# PY32F0xx_DFP register map
Vendor: Puya; Series: PY32F0; File version: 1.0.0
Arm 32-bit Cortex-M0+ Microcontroller based device, CPU clock up to 48 MHz.
CPU: CM0+ r0p1, little endian, no MPU, no FPU, 4 interrupt priority bits
Registers are 32-bit, read-write, reset 0x0 unless marked. A register's access mark holds for its fields unless they carry their own. Offsets are from the block's base; lines under a group give offsets from that group; [hi:lo] are bit positions; {n}, {i} and the like mark numbered series; 'fields as' and 'values as' point back to an identical list; <NAME> marks a mode.

## Memory map
0x40002000 TIM14 size 0x400 — General purpose timer
0x40003000 IWDG size 0x400 — Independent watchdog
0x40007000 PWR size 0x400 — Power control
0x40007C00 LPTIM1 size 0x400 — Low power timer
0x40010000 SYSCFG size 0x30 — System configuration controller
0x40010200 COMP1 size 0x10 — Comparator 1
0x40010210 COMP2 size 0x10 — Comparator2
0x40012C00 TIM1 size 0x400 — Advanced timer
0x40015800 DBGMCU size 0x400 — Debug support
0x40021000 RCC size 0x400 — Reset and clock control
0x40021800 EXTI size 0x400 — External interrupt/event controller
0x40022000 FLASH size 0x400
0x40023000 CRC size 0x400 — CRC calculation unit
0x50000000 GPIOA size 0x400 — General-purpose I/Os
0x50000400 GPIOB size 0x400 — General-purpose I/Os
0x50000800 GPIOC size 0x400

## Interrupts
3 FLASH — FLASH global Interrupt
4 RCC — RCC global Interrupt
5 EXTI0_1 (EXTI) — EXTI Line 0 and 1 Interrupt
6 EXTI2_3 (EXTI) — EXTI Line 2 and 3 Interrupt
7 EXTI4_15 (EXTI) — EXTI Line 4 to 15 Interrupt
12 ADC_COMP (COMP1, COMP2) — ADC and COMP Interrupts
13 TIM1_BRK_UP_TRG_COM (TIM1) — TIM1 Break, Update, Trigger and Commutation Interrupt
14 TIM1_CC (TIM1) — TIM1 Capture Compare Interrupt
17 LPTIM1_DAC (LPTIM1) — LPTIM1, DAC global Interrupts
19 TIM14 — TIM14 global Interrupt

## COMP1 — Comparator 1
Base 0x40010200
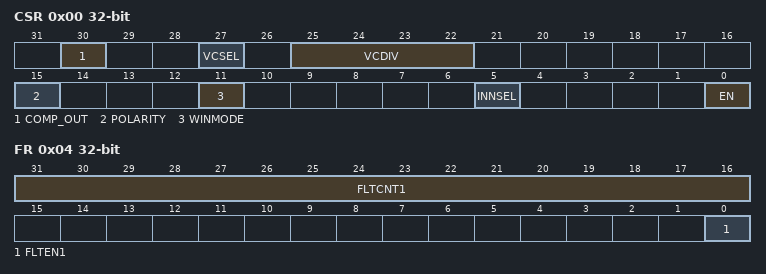
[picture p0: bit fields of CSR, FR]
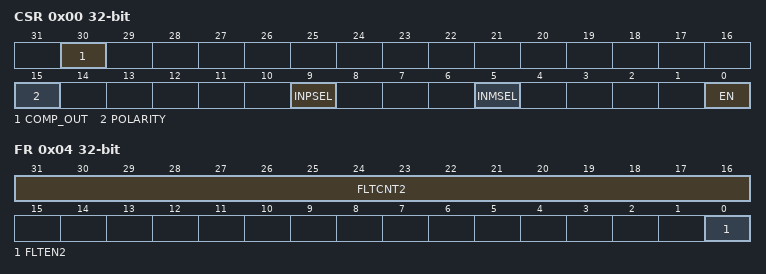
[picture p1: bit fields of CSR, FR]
0x00 CSR — COMP control and status register
  [30] COMP_OUT — Comparator output status
  [27] VCSEL
  [25:22] VCDIV
  [15] POLARITY — Comparator polarity selector
  [11] WINMODE — Comparator non-inverting input selector for window mode
  [5] INNSEL
  [0] EN — COMP enable bit
0x04 FR — Comparator Filter register
  [31:16] FLTCNT1 — Comparator filter and counter
  [0] FLTEN1 — Filter enable bit

## COMP2 — Comparator2
Base 0x40010210
0x00 CSR — COMP control and status register
  [30] COMP_OUT — Comparator output status
  [15] POLARITY — Comparator polarity selector
  [9] INPSEL — Comparator signal selector for non-inverting input
  [5] INMSEL — Comparator signal selector for inverting input INM
  [0] EN — COMP enable bit
0x04 FR — Comparator Filter register
  [31:16] FLTCNT2 — Comparator filter and counter
  [0] FLTEN2 — Filter enable bit

## PWR — Power control
Base 0x40007000
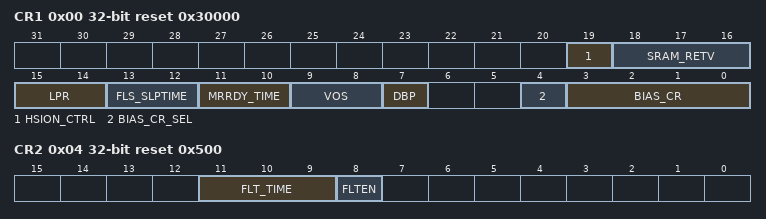
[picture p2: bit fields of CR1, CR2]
0x00 CR1 reset 0x30000 — Power control register 1
  [19] HSION_CTRL — HSI open time control
  [18:16] SRAM_RETV — SRAM retention voltage control
  [15:14] LPR — Low-power run
  [13:12] FLS_SLPTIME — Flash wait time after wakeup from the stop mode
  [11:10] MRRDY_TIME — Time selection wakeup from LP to VR
  [9:8] VOS — Voltage scaling range selection
  [7] DBP — Disable backup domain write protection
  [4] BIAS_CR_SEL — MR Bias current selection
  [3:0] BIAS_CR — MR Bias current
0x04 CR2 reset 0x500 — Power control register 2
  [11:9] FLT_TIME — Digital filter time configuration
  [8] FLTEN — Digital filter enable

## GPIOA — General-purpose I/Os
Base 0x50000000
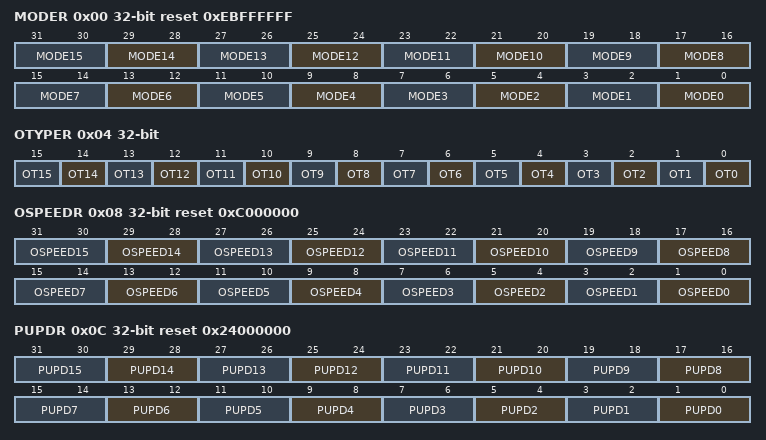
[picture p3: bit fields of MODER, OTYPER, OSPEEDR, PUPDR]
0x00 MODER reset 0xEBFFFFFF — GPIO port mode register
  [2n+1:2n] MODE{n} (n=0..15) — Port x configuration bits (y = 0..15)
0x04 OTYPER — GPIO port output type register
  [n] OT{n} (n=0..15) — Port x configuration bits (y = 0..15)
0x08 OSPEEDR reset 0xC000000 — GPIO port output speed register
  [2n+1:2n] OSPEED{n} (n=0..15) — Port x configuration bits (y = 0..15)
0x0C PUPDR reset 0x24000000 — GPIO port pull-up/pull-down register
  [2n+1:2n] PUPD{n} (n=0..15) — Port x configuration bits (y = 0..15)
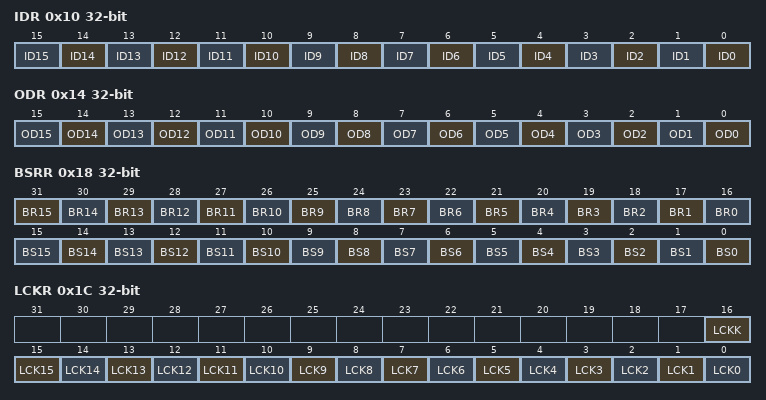
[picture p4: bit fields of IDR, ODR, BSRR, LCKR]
0x10 IDR ro — GPIO port input data register
  [n] ID{n} (n=0..15) — Port input data (y = 0..15)
0x14 ODR — GPIO port output data register
  [n] OD{n} (n=0..15) — Port output data (y = 0..15)
0x18 BSRR wo — GPIO port bit set/reset register
  [n+16] BR{n} (n=1..15) — Port x reset bit y (y = 0..15)
  [16] BR0 — Port x set bit y (y= 0..15)
  [n] BS{n} (n=0..15) — Port x set bit y (y= 0..15)
0x1C LCKR — GPIO port configuration lock register
  [16] LCKK — Port x lock bit y (y= 0..15)
  [n] LCK{n} (n=0..15) — Port x lock bit y (y= 0..15)
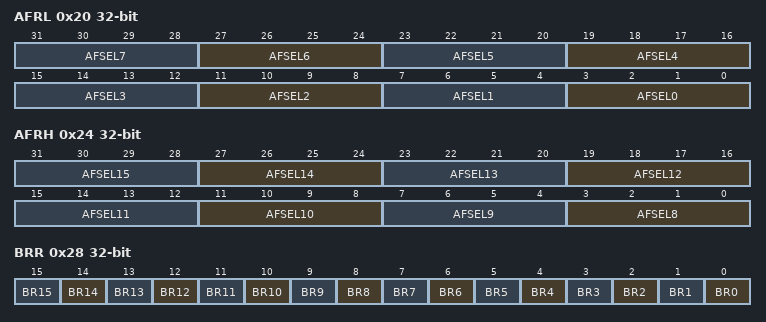
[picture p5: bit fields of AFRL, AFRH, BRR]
0x20 AFRL — GPIO alternate function low register
  [4n+3:4n] AFSEL{n} (n=0..7) — Alternate function selection for port x bit y (y = 0..7)
0x24 AFRH — GPIO alternate function high register
  [4n-29:4n-32] AFSEL{n} (n=8..15) — Alternate function selection for port x bit y (y = 8..15)
0x28 BRR wo — port bit reset register
  [n] BR{n} (n=0..15) — Port Reset bit
